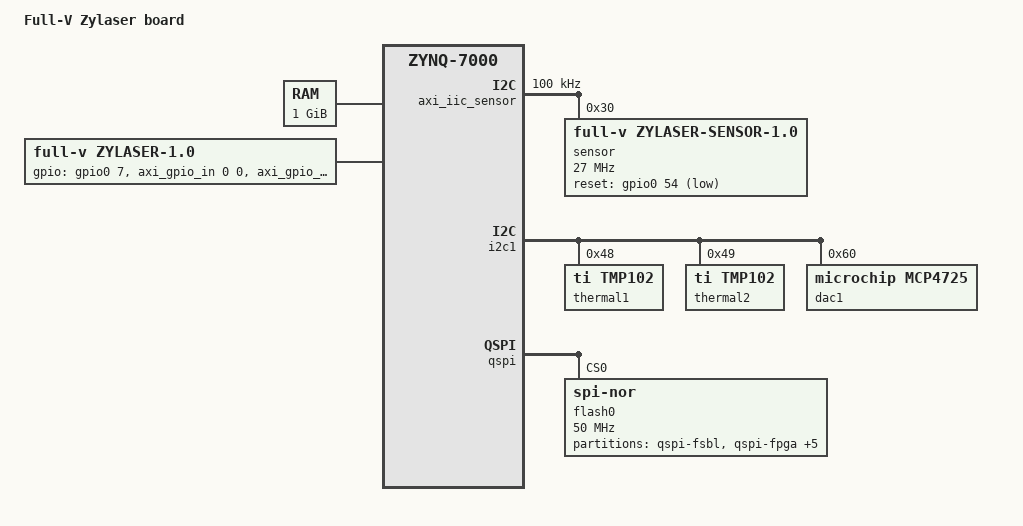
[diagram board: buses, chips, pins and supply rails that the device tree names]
/*
 * CAUTION: This file is automatically generated by Xilinx.
 * Version:  
 * Today is: Tue Oct 27 21:13:41 2020
 */

/dts-v1/;
#include "dt-bindings/gpio/gpio.h"
#include "zynq-7000.dtsi"
#include "zynq-zylaser/pl.dtsi"
#include "zynq-zylaser/pcw.dtsi"

/ {
	model = "Full-V Zylaser board";
	compatible = "fullv,zynq-zylaser", "xlnx,zynq-7000";

	chosen {
		bootargs = "console=ttyPS0,115200 earlycon root=/dev/ram0 rw isolcpus=1";
		stdout-path = "serial0:115200n8";
	};

	aliases {
		ethernet0 = &gem0;
		i2c0 = &i2c0;
		i2c1 = &i2c1;
		i2c2 = &axi_iic_sensor;
		serial0 = &uart0;
		serial1 = &uart1;
		spi0 = &qspi;
	};

	memory {
		device_type = "memory";
		reg = <0x0 0x40000000>;
	};

	reserved-memory {
		#address-cells = <1>;
		#size-cells = <1>;
		ranges;

		/* 64MB global autoconfigured region for contiguous allocations */
		linux,cma@2C000000 {
			compatible = "shared-dma-pool";
			reusable;
			size = <0x4000000>;
			alignment = <0x2000>;
			linux,cma-default;
		};

		/* 256MB for FPGA */
		reserved: buffer@0 {
			compatible = "shared-dma-pool";
			no-map;
			reg = <0x30000000 0x10000000>;
		};
	};

	amba_pl: amba_pl {
		video_ctrl_0: video_ctrl@43c20000 {
			interrupt-parent = <&intc>;
			interrupts = <0 29 4>;
		};

		laser_ctrl_0: laser_ctrl@43c10000 {
			interrupt-parent = <&intc>;
			interrupts = <0 30 4>;
		};
	};

	zylaser {
		compatible = "full-v,zylaser-1.0";
		memory-region = <&reserved>;

		gpios = <&gpio0 7 0>,
			<&axi_gpio_in 0 0 0>,
			<&axi_gpio_in 1 0 0>,
			<&axi_gpio_in 2 0 0>,
			<&axi_gpio_in 3 0 0>,
			<&axi_gpio_in 4 0 0>,
			<&axi_gpio_in 5 0 0>,
			<&axi_gpio_in 6 0 0>,
			<&axi_gpio_in 7 0 0>,
			<&axi_gpio_out 0 0 0>,
			<&axi_gpio_out 1 0 0>,
			<&axi_gpio_out 2 0 0>,
			<&axi_gpio_out 3 0 0>,
			<&axi_gpio_out 4 0 0>,
			<&axi_gpio_out 5 0 0>,
			<&axi_gpio_out 6 0 0>,
			<&axi_gpio_out 7 0 0>,
			<&axi_gpio_out 8 0 0>,
			<&axi_gpio_out 9 0 0>,
			<&axi_gpio_out 10 0 0>;
	};
};

&axi_iic_sensor {
	clock-frequency = <100000>;
	status = "okay";

	sensor@30 {
		compatible = "full-v,zylaser-sensor-1.0", "smartsens,sc2210";
		reg = <0x30>;
		reset-gpios = <&gpio0 54 GPIO_ACTIVE_LOW>;
		clock-frequency = <27000000>;
	};
};

&gem0 {
	local-mac-address = [00 0a 35 00 00 00];
};

&i2c1 {
	thermal1@48 {
		compatible = "ti,tmp102";
		reg = <0x48>;
	};

	thermal2@49 {
		compatible = "ti,tmp102";
		reg = <0x49>;
	};

	dac1@60 {
		compatible = "microchip,mcp4725";
		reg = <0x60>;
	};
};

&qspi {
	#address-cells = <1>;
	#size-cells = <0>;

	flash0: flash@0 {
		compatible = "jedec,spi-nor";
		reg = <0>;
		spi-max-frequency = <50000000>;

		partitions {
			#address-cells = <1>;
			#size-cells = <1>;
			compatible = "fixed-partitions";

			partition@0 {
				label = "qspi-fsbl";
				reg = <0x00000000 0x00040000>;
			};
			partition@1 {
				label = "qspi-fpga";
				reg = <0x00040000 0x00500000>;
			};
			partition@2 {
				label = "qspi-uboot";
				reg = <0x00540000 0x000C0000>;
			};
			partition@3 {
				label = "qspi-bootenv";
				reg = <0x00600000 0x00020000>;
			};
			partition@4 {
				label = "qspi-bootscr";
				reg = <0x00640000 0x00040000>;
			};
			partition@5 {
				label = "qspi-misc";
				reg = <0x00680000 0x00400000>;
			};
			partition@6 {
				label = "qspi-spare";
				reg = <0x00A80000 0x00000000>;
			};
		};
	};
};
